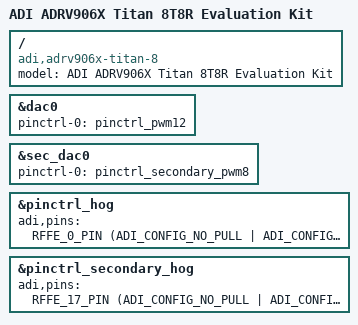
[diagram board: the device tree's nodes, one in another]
// SPDX-License-Identifier: GPL-2.0
/*
 * Copyright (c) 2024, Analog Devices Incorporated, All Rights Reserved
 */

/* For now, Titan-8 is identical to Denali-8 except for the changes below */
#include "adrv906x-denali-8.dts"

/ {
	model = "ADI ADRV906X Titan 8T8R Evaluation Kit";
	compatible = "adi,adrv906x-titan-8", "adi,adrv906x";
};

&dac0 {
	status = "okay";
	pinctrl-names = "default";
	pinctrl-0 = <&pinctrl_pwm12>;
};

&sec_dac0 {
	status = "okay";
	pinctrl-names = "default";
	pinctrl-0 = <&pinctrl_secondary_pwm8>;
};

/*
 * GPIO Pin mapping: 
 * 
 * Pin 0-6:     SD
 * Pins 7-19:	RFFE
 * Pins 20-21: 	I2C
 * Pins 22-23:	Stream processor fault handling
 * Pins 24-27:	UART0
 * Pins 28-29: 	Not Connected
 * Pins 30-31: 	UART4
 * Pin 32:		GPINT0
 * Pins 33-37: 	RFFE
 * Pins 38-39:	JTAG M4
 * Pins 40-41:	RFFE
 * Pin 42:		SPI_MASTER0_SELB_1
 * Pin 43: 		RFFE
 * Pin 44:		TRACE_D2
 * Pin 45: 		ONE_PPS_CLK_OUTPUT_SE
 * Pin 46: 		PWM_12
 * Pin 47:		RFFE
 * Pin 51:		Board pushbutton
 * Pins 52-53:	Not Connected
 * Pins 54-55:	RFFE
 * Pins 56-59:	QSFP Interface
 * Pins 60-64:  JTAG A5
 * Pins 65-69:	RFFE
 * Pins 70-73:	QSFP Interface
 * Pins 74-77: 	Gpio LEDs
 * Pins 78-84: 	QSPI
 * Pins 85-100: EMAC
 * Pin 101:		GPINT_INTERRUPT_INPUT_SECONDARY_TO_PRIMARY
 * Pin 102: 	A55_GPIO_S_102_PIN (reboot/shutdown signal to ADM12366)
 */
&pinctrl_hog {
	adi,pins = <
	/* RFFE signals */
	RFFE_0_PIN		(ADI_CONFIG_NO_PULL  | ADI_CONFIG_DRIVE_STRENGTH_4)
	RFFE_1_PIN		(ADI_CONFIG_NO_PULL  | ADI_CONFIG_DRIVE_STRENGTH_4)
	RFFE_2_PIN		(ADI_CONFIG_NO_PULL  | ADI_CONFIG_DRIVE_STRENGTH_4)
	RFFE_3_PIN		(ADI_CONFIG_NO_PULL  | ADI_CONFIG_DRIVE_STRENGTH_4)
	RFFE_4_PIN		(ADI_CONFIG_NO_PULL  | ADI_CONFIG_DRIVE_STRENGTH_4)
	RFFE_5_PIN		(ADI_CONFIG_NO_PULL  | ADI_CONFIG_DRIVE_STRENGTH_4)
	RFFE_6_PIN		(ADI_CONFIG_NO_PULL  | ADI_CONFIG_DRIVE_STRENGTH_4)
	RFFE_7_PIN		(ADI_CONFIG_NO_PULL  | ADI_CONFIG_DRIVE_STRENGTH_4)
	RFFE_8_PIN		(ADI_CONFIG_NO_PULL  | ADI_CONFIG_DRIVE_STRENGTH_4)
	RFFE_9_PIN		(ADI_CONFIG_NO_PULL  | ADI_CONFIG_DRIVE_STRENGTH_4)
	RFFE_10_PIN		(ADI_CONFIG_NO_PULL  | ADI_CONFIG_DRIVE_STRENGTH_4)
	RFFE_11_PIN		(ADI_CONFIG_NO_PULL  | ADI_CONFIG_DRIVE_STRENGTH_4)
	RFFE_12_PIN		(ADI_CONFIG_NO_PULL  | ADI_CONFIG_DRIVE_STRENGTH_4)

	RFFE_19_PIN		(ADI_CONFIG_NO_PULL  | ADI_CONFIG_DRIVE_STRENGTH_4)
	RFFE_20_PIN		(ADI_CONFIG_NO_PULL  | ADI_CONFIG_DRIVE_STRENGTH_4)
	RFFE_21_PIN		(ADI_CONFIG_NO_PULL  | ADI_CONFIG_DRIVE_STRENGTH_4)
	RFFE_22_PIN		(ADI_CONFIG_NO_PULL  | ADI_CONFIG_DRIVE_STRENGTH_4)
	
	RFFE_30_PIN		(ADI_CONFIG_NO_PULL  | ADI_CONFIG_DRIVE_STRENGTH_4)
	RFFE_31_PIN		(ADI_CONFIG_NO_PULL  | ADI_CONFIG_DRIVE_STRENGTH_4)
	RFFE_32_PIN		(ADI_CONFIG_NO_PULL  | ADI_CONFIG_DRIVE_STRENGTH_4)
	RFFE_33_PIN		(ADI_CONFIG_NO_PULL  | ADI_CONFIG_DRIVE_STRENGTH_4)
	RFFE_34_PIN		(ADI_CONFIG_NO_PULL  | ADI_CONFIG_DRIVE_STRENGTH_4)
	RFFE_37_PIN		(ADI_CONFIG_NO_PULL  | ADI_CONFIG_DRIVE_STRENGTH_4)
	RFFE_38_PIN		(ADI_CONFIG_NO_PULL  | ADI_CONFIG_DRIVE_STRENGTH_4)
	RFFE_39_PIN		(ADI_CONFIG_NO_PULL  | ADI_CONFIG_DRIVE_STRENGTH_4)
	RFFE_40_PIN		(ADI_CONFIG_NO_PULL  | ADI_CONFIG_DRIVE_STRENGTH_4)
	RFFE_44_PIN		(ADI_CONFIG_NO_PULL  | ADI_CONFIG_DRIVE_STRENGTH_4)
	RFFE_45_PIN		(ADI_CONFIG_NO_PULL  | ADI_CONFIG_DRIVE_STRENGTH_4)
	RFFE_46_PIN		(ADI_CONFIG_NO_PULL  | ADI_CONFIG_DRIVE_STRENGTH_4)

	/* Pins 22-23: Stream processor fault handling */
	A55_GPIO_NS_22_PIN	(ADI_CONFIG_ENABLE_PULLDOWN | ADI_CONFIG_DRIVE_STRENGTH_4)
	A55_GPIO_NS_23_PIN	(ADI_CONFIG_ENABLE_SCHMITT_TRIGGER)

	/* Pin 51: Board pushbutton */
	A55_GPIO_NS_51_PIN	(ADI_CONFIG_ENABLE_SCHMITT_TRIGGER)

	/* QSFP */
	A55_GPIO_NS_56_PIN	(ADI_CONFIG_NO_PULL  | ADI_CONFIG_DRIVE_STRENGTH_4) /* QSFP_RESET_L */
	A55_GPIO_NS_57_PIN	(ADI_CONFIG_ENABLE_SCHMITT_TRIGGER) /* QSFP_INT_L */
	A55_GPIO_NS_58_PIN	(ADI_CONFIG_NO_PULL  | ADI_CONFIG_DRIVE_STRENGTH_4) /* QSFP_MODSEL_L */
	A55_GPIO_NS_59_PIN	(ADI_CONFIG_ENABLE_SCHMITT_TRIGGER) /* QSFP_MODPRS_L */
	A55_GPIO_NS_70_PIN	(ADI_CONFIG_NO_PULL  | ADI_CONFIG_DRIVE_STRENGTH_4) /* QSFP LP Mode */
	>;
};

/*
 * GPIO Pin mapping: 
 * 
 * Pin 0-3:     SPI3
 * Pin 6:		Not Connected
 * Pins 7-8:	RFFE
 * Pins 9-11:	Not Connected
 * Pin 17:		Not Connected
 * Pin 18-19:	RFFE
 * Pins 20-21: 	Not Connected
 * Pins 22-23:	Stream processor fault handling
 * Pins 24-27:	UART0
 * Pins 28-31: 	AISG
 * Pin 32:		GPINT0
 * Pin 37:	 	RFFE
 * Pin 38:		PWM_8
 * Pins 39-41:	RFFE
 * Pin 42:		AISG
 * Pin 43: 		RFFE
 * Pin 44:		Not Connected
 * Pins 45-49: 	SPI1
 * Pin 50:		Not Connected
 * Pins 51-53:	Not Connected
 * Pins 54-55:	RFFE
 * Pins 56-59:	Not Connected
 * Pins 60-64:  JTAG A5
 * Pins 65-69:	RFFE
 * Pins 74-77: 	Gpio LEDs
 * Pins 78-102:	Not Connected
 */
&pinctrl_secondary_hog {
	adi,pins = <

	/* RFFE pins on secondary tile */
	RFFE_17_PIN		(ADI_CONFIG_NO_PULL  | ADI_CONFIG_DRIVE_STRENGTH_4) /* PREAMP_0_TO_3_EN                               */
	RFFE_18_PIN		(ADI_CONFIG_NO_PULL  | ADI_CONFIG_DRIVE_STRENGTH_4) /* PREAMP_4_TO_7_EN                               */
	RFFE_0_PIN		(ADI_CONFIG_NO_PULL  | ADI_CONFIG_DRIVE_STRENGTH_4) /* RFFE FUNCTIONALITY (PA4_EN)                    */
	RFFE_1_PIN		(ADI_CONFIG_NO_PULL  | ADI_CONFIG_DRIVE_STRENGTH_4) /* RFFE FUNCTIONALITY (LNA4_EN)                   */
	RFFE_5_PIN		(ADI_CONFIG_NO_PULL  | ADI_CONFIG_DRIVE_STRENGTH_4) /* RFFE FUNCTIONALITY (T_R_Switch_Control_4_7)    */
	RFFE_6_PIN		(ADI_CONFIG_NO_PULL  | ADI_CONFIG_DRIVE_STRENGTH_4) /* RFFE FUNCTIONALITY (SS_TxToORxMap_DPD_LOL_D0)  */
	RFFE_7_PIN		(ADI_CONFIG_NO_PULL  | ADI_CONFIG_DRIVE_STRENGTH_4) /* RFFE FUNCTIONALITY (SS_TxToORxMap_DPD_LOL_D1)  */
	RFFE_8_PIN		(ADI_CONFIG_NO_PULL  | ADI_CONFIG_DRIVE_STRENGTH_4) /* RFFE FUNCTIONALITY (SS_TxToORxMap_DPD_LOL_D2)  */
	RFFE_9_PIN		(ADI_CONFIG_NO_PULL  | ADI_CONFIG_DRIVE_STRENGTH_4) /* RFFE FUNCTIONALITY (SS_DPD_VSWR_SW_CTRL)       */
	RFFE_11_PIN		(ADI_CONFIG_NO_PULL  | ADI_CONFIG_DRIVE_STRENGTH_4) /* RFFE FUNCTIONALITY (PA5_EN)                    */
	RFFE_12_PIN		(ADI_CONFIG_NO_PULL  | ADI_CONFIG_DRIVE_STRENGTH_4) /* RFFE FUNCTIONALITY (PA6_EN)                    */
	RFFE_30_PIN		(ADI_CONFIG_NO_PULL  | ADI_CONFIG_DRIVE_STRENGTH_4) /* RFFE FUNCTIONALITY (PA7_EN)                    */
	RFFE_31_PIN		(ADI_CONFIG_NO_PULL  | ADI_CONFIG_DRIVE_STRENGTH_4) /* RFFE FUNCTIONALITY (LNA5_EN)                   */
	RFFE_32_PIN		(ADI_CONFIG_NO_PULL  | ADI_CONFIG_DRIVE_STRENGTH_4) /* RFFE FUNCTIONALITY (LNA6_EN)                   */
	RFFE_33_PIN		(ADI_CONFIG_NO_PULL  | ADI_CONFIG_DRIVE_STRENGTH_4) /* RFFE FUNCTIONALITY (LNA7_EN)                   */
	RFFE_34_PIN		(ADI_CONFIG_NO_PULL  | ADI_CONFIG_DRIVE_STRENGTH_4) /* RFFE FUNCTIONALITY (PA4_ET_D0)                 */
	RFFE_36_PIN		(ADI_CONFIG_NO_PULL  | ADI_CONFIG_DRIVE_STRENGTH_4) /* RFFE FUNCTIONALITY (PA7_ET_D0)                 */
	RFFE_37_PIN		(ADI_CONFIG_NO_PULL  | ADI_CONFIG_DRIVE_STRENGTH_4) /* RFFE FUNCTIONALITY (PA5_ET_D0)                 */
	RFFE_38_PIN		(ADI_CONFIG_NO_PULL  | ADI_CONFIG_DRIVE_STRENGTH_4) /* RFFE FUNCTIONALITY (PA5_ET_D1)                 */
	RFFE_39_PIN		(ADI_CONFIG_NO_PULL  | ADI_CONFIG_DRIVE_STRENGTH_4) /* RFFE FUNCTIONALITY (PA6_ET_D0)                 */
	RFFE_44_PIN		(ADI_CONFIG_NO_PULL  | ADI_CONFIG_DRIVE_STRENGTH_4) /* RFFE FUNCTIONALITY (PA5_ET_TSYNC)              */
	RFFE_45_PIN		(ADI_CONFIG_NO_PULL  | ADI_CONFIG_DRIVE_STRENGTH_4) /* RFFE FUNCTIONALITY (PA7_ET_D1)                 */
	RFFE_46_PIN		(ADI_CONFIG_NO_PULL  | ADI_CONFIG_DRIVE_STRENGTH_4) /* RFFE FUNCTIONALITY (PA6_ET_D1)                 */
	RFFE_19_PIN		(ADI_CONFIG_NO_PULL  | ADI_CONFIG_DRIVE_STRENGTH_4) /* RFFE FUNCTIONALITY (PA4_ET_D1)                 */
	RFFE_20_PIN		(ADI_CONFIG_NO_PULL  | ADI_CONFIG_DRIVE_STRENGTH_4) /* RFFE FUNCTIONALITY (PA4_ET_TSYNC)              */
	RFFE_21_PIN		(ADI_CONFIG_NO_PULL  | ADI_CONFIG_DRIVE_STRENGTH_4) /* RFFE FUNCTIONALITY (PA7_ET_TSYNC)              */
	RFFE_22_PIN		(ADI_CONFIG_NO_PULL  | ADI_CONFIG_DRIVE_STRENGTH_4) /* RFFE FUNCTIONALITY (PA6_ET_TSYNC)              */

	/* Pins 22-23: Stream processor fault handling */
	A55_GPIO_NS_22_PIN	(ADI_CONFIG_ENABLE_PULLDOWN | ADI_CONFIG_DRIVE_STRENGTH_4) /* INTERRUPT_PS_TO_SS */
	A55_GPIO_NS_23_PIN	(ADI_CONFIG_ENABLE_SCHMITT_TRIGGER)  /* CONFIRMATION_SS_TO_PS */

	A55_GPIO_NS_42_PIN (ADI_CONFIG_ENABLE_SCHMITT_TRIGGER) /* AISG1_DIR */
	A55_GPIO_NS_50_PIN (ADI_CONFIG_ENABLE_SCHMITT_TRIGGER) /* AISG0_DIR */
	>;
};
